# STM32L053 register map
File version: 1.0
CPU: CM0+ r0p0, little endian, MPU, no FPU, 4 interrupt priority bits
Registers are 32-bit, read-write, reset 0x0 unless marked. A register's access mark holds for its fields unless they carry their own. Offsets are from the block's base; [hi:lo] are bit positions; {n}, {i} and the like mark numbered series.

## CRC — Cyclic redundancy check calculation unit
Base 0x40023000
0x00 DR reset 0xFFFFFFFF — Data register
  [31:0] DR — Data register bits
0x04 IDR — Independent data register
  [7:0] IDR — General-purpose 8-bit data register bits
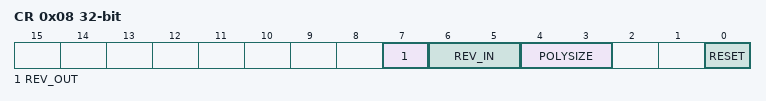
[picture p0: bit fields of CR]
0x08 CR access per field — Control register
  [7] REV_OUT rw — Reverse output data
  [6:5] REV_IN rw — Reverse input data
  [4:3] POLYSIZE rw — Polynomial size
  [0] RESET wo — RESET bit
0x10 INIT reset 0xFFFFFFFF — Initial CRC value
  [31:0] CRC_INIT — Programmable initial CRC value
0x14 POL reset 0x4C11DB7 — polynomial
  [31:0] Polynomialcoefficients — Programmable polynomial

## GPIOA — General-purpose I/Os
Base 0x50000000
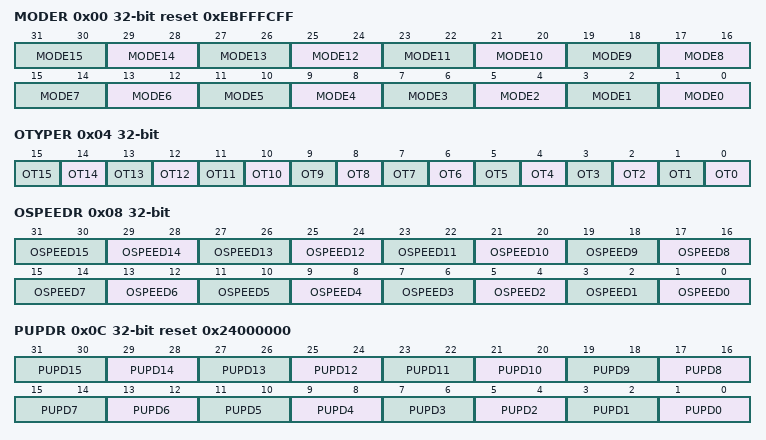
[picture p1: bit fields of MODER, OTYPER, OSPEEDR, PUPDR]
0x00 MODER reset 0xEBFFFCFF — GPIO port mode register
  [2n+1:2n] MODE{n} (n=0..15) — Port x configuration bits (y = 0..15)
0x04 OTYPER — GPIO port output type register
  [n] OT{n} (n=0..15) — Port x configuration bits (y = 0..15)
0x08 OSPEEDR — GPIO port output speed register
  [2n+1:2n] OSPEED{n} (n=0..15) — Port x configuration bits (y = 0..15)
0x0C PUPDR reset 0x24000000 — GPIO port pull-up/pull-down register
  [2n+1:2n] PUPD{n} (n=0..15) — Port x configuration bits (y = 0..15)
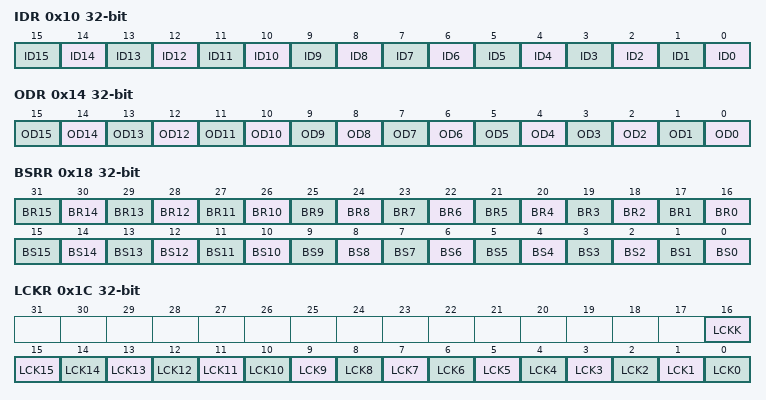
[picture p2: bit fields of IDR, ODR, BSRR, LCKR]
0x10 IDR ro — GPIO port input data register
  [n] ID{n} (n=0..15) — Port input data bit (y = 0..15)
0x14 ODR — GPIO port output data register
  [n] OD{n} (n=0..15) — Port output data bit (y = 0..15)
0x18 BSRR wo — GPIO port bit set/reset register
  [n+16] BR{n} (n=0..15) — Port x reset bit y (y = 0..15)
  [n] BS{n} (n=0..15) — Port x set bit y (y= 0..15)
0x1C LCKR — GPIO port configuration lock register
  [16] LCKK — Port x lock bit y (y= 0..15)
  [n] LCK{n} (n=0..15) — Port x lock bit y (y= 0..15)
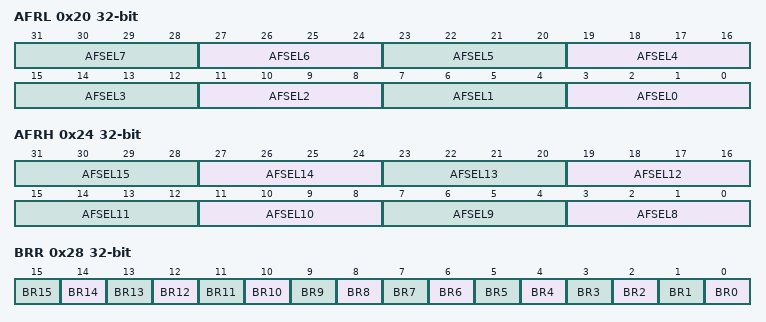
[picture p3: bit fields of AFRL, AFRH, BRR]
0x20 AFRL — GPIO alternate function low register
  [4n+3:4n] AFSEL{n} (n=0..7) — Alternate function selection for port x pin y (y = 0..7)
0x24 AFRH — GPIO alternate function high register
  [4n-29:4n-32] AFSEL{n} (n=8..15) — Alternate function selection for port x pin y (y = 8..15)
0x28 BRR wo — GPIO port bit reset register
  [n] BR{n} (n=0..15) — Port x Reset bit y (y= 0 .. 15)

## GPIOB — General-purpose I/Os
Base 0x50000400
Same registers: GPIOC 0x50000800, GPIOD 0x50000C00, GPIOE 0x50001000, GPIOH 0x50001C00
Registers as GPIOA; these are added or differ:
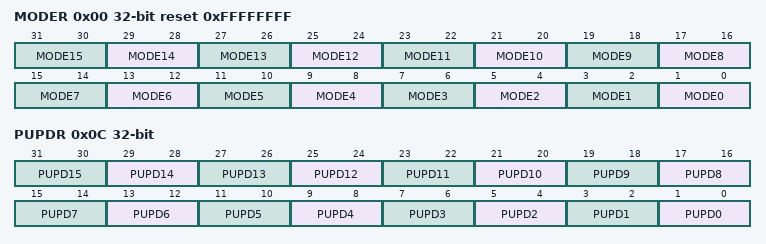
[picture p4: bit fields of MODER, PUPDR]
0x00 MODER reset 0xFFFFFFFF — GPIO port mode register
  [2n+1:2n] MODE{n} (n=0..15) — Port x configuration bits (y = 0..15)
0x0C PUPDR — GPIO port pull-up/pull-down register
  [2n+1:2n] PUPD{n} (n=0..15) — Port x configuration bits (y = 0..15)

## LPTIM — Low power timer
Base 0x40007C00
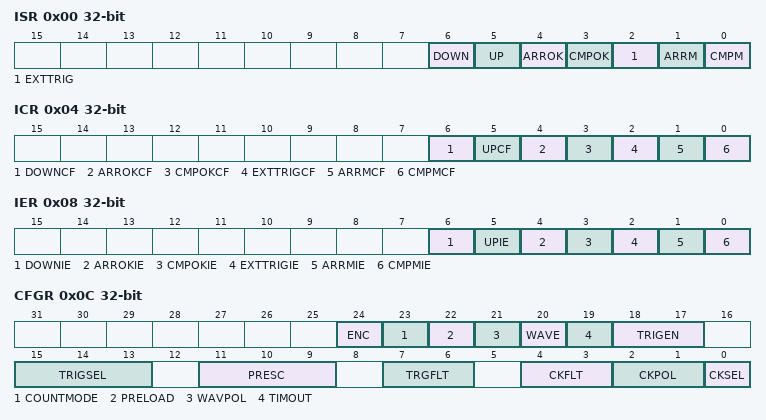
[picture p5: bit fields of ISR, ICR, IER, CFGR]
0x00 ISR ro — Interrupt and Status Register
  [6] DOWN — Counter direction change up to down
  [5] UP — Counter direction change down to up
  [4] ARROK — Autoreload register update OK
  [3] CMPOK — Compare register update OK
  [2] EXTTRIG — External trigger edge event
  [1] ARRM — Autoreload match
  [0] CMPM — Compare match
0x04 ICR wo — Interrupt Clear Register
  [6] DOWNCF — Direction change to down Clear Flag
  [5] UPCF — Direction change to UP Clear Flag
  [4] ARROKCF — Autoreload register update OK Clear Flag
  [3] CMPOKCF — Compare register update OK Clear Flag
  [2] EXTTRIGCF — External trigger valid edge Clear Flag
  [1] ARRMCF — Autoreload match Clear Flag
  [0] CMPMCF — compare match Clear Flag
0x08 IER — Interrupt Enable Register
  [6] DOWNIE — Direction change to down Interrupt Enable
  [5] UPIE — Direction change to UP Interrupt Enable
  [4] ARROKIE — Autoreload register update OK Interrupt Enable
  [3] CMPOKIE — Compare register update OK Interrupt Enable
  [2] EXTTRIGIE — External trigger valid edge Interrupt Enable
  [1] ARRMIE — Autoreload match Interrupt Enable
  [0] CMPMIE — Compare match Interrupt Enable
0x0C CFGR — Configuration Register
  [24] ENC — Encoder mode enable
  [23] COUNTMODE — counter mode enabled
  [22] PRELOAD — Registers update mode
  [21] WAVPOL — Waveform shape polarity
  [20] WAVE — Waveform shape
  [19] TIMOUT — Timeout enable
  [18:17] TRIGEN — Trigger enable and polarity
  [15:13] TRIGSEL — Trigger selector
  [11:9] PRESC — Clock prescaler
  [7:6] TRGFLT — Configurable digital filter for trigger
  [4:3] CKFLT — Configurable digital filter for external clock
  [2:1] CKPOL — Clock Polarity
  [0] CKSEL — Clock selector
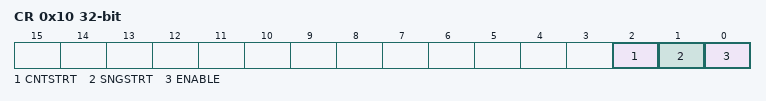
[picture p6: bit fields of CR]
0x10 CR — Control Register
  [2] CNTSTRT — Timer start in continuous mode
  [1] SNGSTRT — LPTIM start in single mode
  [0] ENABLE — LPTIM Enable
0x14 CMP — Compare Register
  [15:0] CMP — Compare value.
0x18 ARR reset 0x1 — Autoreload Register
  [15:0] ARR — Auto reload value.
0x1C CNT ro — Counter Register
  [15:0] CNT — Counter value.
